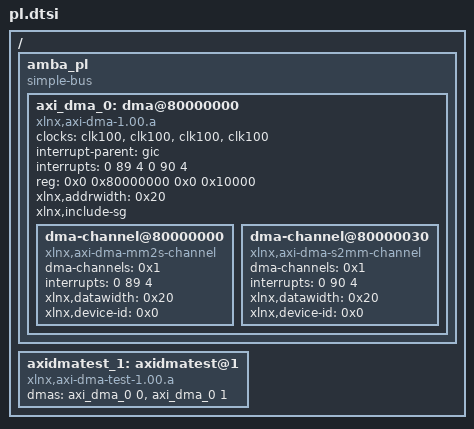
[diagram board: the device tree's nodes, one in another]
/*
 * Programmable logic dtsi file for use with the Alion Soteria board
 *
 * Kyle Faulkner <kfaulkner@alionscience.com>
 *
 * This program is free software; you can redistribute it and/or
 * modify it under the terms of the GNU General Public License as
 * published by the Free Software Foundation; either version 2 of
 * the License, or (at your option) any later version.
 */

/ {
   amba_pl: amba_pl {
      #address-cells = <2>;
      #size-cells = <2>;
      compatible = "simple-bus";
      ranges ;
      axi_dma_0: dma@80000000 {
         #dma-cells = <1>;

         clock-names = "s_axi_lite_aclk", "m_axi_sg_aclk", "m_axi_mm2s_aclk", "m_axi_s2mm_aclk";
         clocks = <&clk100>, <&clk100>, <&clk100>, <&clk100>;
         compatible = "xlnx,axi-dma-1.00.a";
         interrupt-parent = <&gic>;
         interrupts = <0 89 4 0 90 4>;
         reg = <0x0 0x80000000 0x0 0x10000>;
         xlnx,addrwidth = <0x20>;
         xlnx,include-sg ;
         dma-channel@80000000 {
            compatible = "xlnx,axi-dma-mm2s-channel";
            dma-channels = <0x1>;
            interrupts = <0 89 4>;
            xlnx,datawidth = <0x20>;
            xlnx,device-id = <0x0>;
         };
         dma-channel@80000030 {
            compatible = "xlnx,axi-dma-s2mm-channel";
            dma-channels = <0x1>;
            interrupts = <0 90 4>;
            xlnx,datawidth = <0x20>;
            xlnx,device-id = <0x0>;
         };
      };
   };

   axidmatest_1: axidmatest@1 {
      compatible ="xlnx,axi-dma-test-1.00.a";
      dmas = <&axi_dma_0 0
              &axi_dma_0 1>;
      dma-names = "axidma0", "axidma1";
 } ;
};
